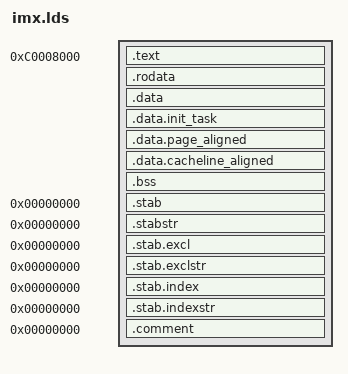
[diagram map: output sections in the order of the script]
OUTPUT_ARCH(arm)
ENTRY(_start)
SECTIONS
{
  . = 0xC0008000;
  _text = .;			/* Text and read-only data */
  .text : {
	*(.text)
	*(.gnu.warning)
	} = 0x9090

  _etext = .;			/* End of text section */

  .rodata : { *(.rodata) *(.rodata.*) }

  .data : {			/* Data */
	*(.data)
	CONSTRUCTORS
	}

  _edata = .;			/* End of data section */

  . = ALIGN(8192);		/* init_task */
  .data.init_task : { *(.data.init_task) }

  . = ALIGN(4096);
  .data.page_aligned : { *(.data.idt) }

  . = ALIGN(32);
  .data.cacheline_aligned : { *(.data.cacheline_aligned) }

  . = ALIGN(8*1024);
  __bss_start = .;		/* BSS */
  .bss : {
	__stack_end = .;
	*(.bss.stack_aligned)
	__stack_start = .;
	*(.bss.page_aligned)
	*(.bss)
	}
  _end = . ;

  /* Sections to be discarded */
  /DISCARD/ : {
	*(.text.exit)
	*(.data.exit)
	*(.exitcall.exit)
	}

  /* Stabs debugging sections.  */
  .stab 0 : { *(.stab) }
  .stabstr 0 : { *(.stabstr) }
  .stab.excl 0 : { *(.stab.excl) }
  .stab.exclstr 0 : { *(.stab.exclstr) }
  .stab.index 0 : { *(.stab.index) }
  .stab.indexstr 0 : { *(.stab.indexstr) }
  .comment 0 : { *(.comment) }
}
